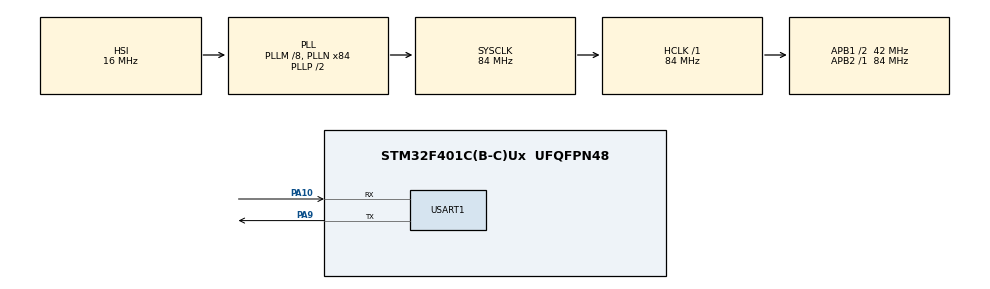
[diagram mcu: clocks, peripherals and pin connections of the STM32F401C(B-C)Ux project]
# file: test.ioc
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Mcu.Family=STM32F4
Mcu.Name=STM32F401C(B-C)Ux
Mcu.Package=UFQFPN48
NVIC.PriorityGroup=NVIC_PRIORITYGROUP_4
PA10.Mode=Asynchronous
PA10.Signal=USART1_RX
PA13.Mode=Serial_Wire
PA13.Signal=SYS_JTMS-SWDIO
PA14.Mode=Serial_Wire
PA14.Signal=SYS_JTCK-SWCLK
PA9.Mode=Asynchronous
PA9.Signal=USART1_TX
PC14-OSC32_IN.Mode=LSE-External-Oscillator
PC14-OSC32_IN.Signal=RCC_OSC32_IN
PC15-OSC32_OUT.Mode=LSE-External-Oscillator
PC15-OSC32_OUT.Signal=RCC_OSC32_OUT
PH0\ -\ OSC_IN.Mode=HSE-External-Oscillator
PH0\ -\ OSC_IN.Signal=RCC_OSC_IN
PH1\ -\ OSC_OUT.Mode=HSE-External-Oscillator
PH1\ -\ OSC_OUT.Signal=RCC_OSC_OUT
ProjectManager.HeapSize=0x200
ProjectManager.StackSize=0x400
ProjectManager.TargetToolchain=EWARM V8
RCC.48MHZClocksFreq_Value=42000000
RCC.AHBFreq_Value=84000000
RCC.APB1CLKDivider=RCC_HCLK_DIV2
RCC.APB1Freq_Value=42000000
RCC.APB1TimFreq_Value=84000000
RCC.APB2Freq_Value=84000000
RCC.APB2TimFreq_Value=84000000
RCC.CortexFreq_Value=84000000
RCC.HCLKFreq_Value=84000000
RCC.HSE_VALUE=25000000
RCC.HSI_VALUE=16000000
RCC.PLLM=8
RCC.PLLN=84
RCC.SYSCLKFreq_VALUE=84000000
RCC.SYSCLKSource=RCC_SYSCLKSOURCE_PLLCLK
RCC.VCOOutputFreq_Value=168000000
USART1.VirtualMode=VM_ASYNC
board=custom

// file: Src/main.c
/* USER CODE BEGIN Header */
/**
  ******************************************************************************
  * @file           : main.c
  * @brief          : Main program body
  ******************************************************************************
  * @attention
  *
  * <h2><center>&copy; Copyright (c) 2020 STMicroelectronics.
  * All rights reserved.</center></h2>
  *
  * This software component is licensed by ST under BSD 3-Clause license,
  * the "License"; You may not use this file except in compliance with the
  * License. You may obtain a copy of the License at:
  *                        opensource.org/licenses/BSD-3-Clause
  *
  ******************************************************************************
  */
/* USER CODE END Header */

#include "main.h"

UART_HandleTypeDef huart1;

void SystemClock_Config(void);
static void MX_GPIO_Init(void);
static void MX_USART1_UART_Init(void);

int main(void)
{

  /* MCU Configuration--------------------------------------------------------*/

  /* Reset of all peripherals, Initializes the Flash interface and the Systick. */
  HAL_Init();

  /* Configure the system clock */
  SystemClock_Config();

  /* Initialize all configured peripherals */
  MX_GPIO_Init();
  MX_USART1_UART_Init();

  /* Infinite loop */
  while (1)
  {

	/* USER CODE BEGIN 3 */
	char str[] = "hello world\n";
    HAL_UART_Transmit(&huart1,(uint8_t *)str,sizeof(str),1000);
    HAL_Delay(1000);
  }
  /* USER CODE END 3 */
}

void SystemClock_Config(void)
{
  RCC_OscInitTypeDef RCC_OscInitStruct = {0};
  RCC_ClkInitTypeDef RCC_ClkInitStruct = {0};

  /** Configure the main internal regulator output voltage
  */
  __HAL_RCC_PWR_CLK_ENABLE();
  __HAL_PWR_VOLTAGESCALING_CONFIG(PWR_REGULATOR_VOLTAGE_SCALE2);
  /** Initializes the CPU, AHB and APB busses clocks
  */
  RCC_OscInitStruct.OscillatorType = RCC_OSCILLATORTYPE_HSI;
  RCC_OscInitStruct.HSIState = RCC_HSI_ON;
  RCC_OscInitStruct.HSICalibrationValue = RCC_HSICALIBRATION_DEFAULT;
  RCC_OscInitStruct.PLL.PLLState = RCC_PLL_ON;
  RCC_OscInitStruct.PLL.PLLSource = RCC_PLLSOURCE_HSI;
  RCC_OscInitStruct.PLL.PLLM = 8;
  RCC_OscInitStruct.PLL.PLLN = 84;
  RCC_OscInitStruct.PLL.PLLP = RCC_PLLP_DIV2;
  RCC_OscInitStruct.PLL.PLLQ = 4;
  if (HAL_RCC_OscConfig(&RCC_OscInitStruct) != HAL_OK)
  {
    Error_Handler();
  }
  /** Initializes the CPU, AHB and APB busses clocks
  */
  RCC_ClkInitStruct.ClockType = RCC_CLOCKTYPE_HCLK|RCC_CLOCKTYPE_SYSCLK
                              |RCC_CLOCKTYPE_PCLK1|RCC_CLOCKTYPE_PCLK2;
  RCC_ClkInitStruct.SYSCLKSource = RCC_SYSCLKSOURCE_PLLCLK;
  RCC_ClkInitStruct.AHBCLKDivider = RCC_SYSCLK_DIV1;
  RCC_ClkInitStruct.APB1CLKDivider = RCC_HCLK_DIV2;
  RCC_ClkInitStruct.APB2CLKDivider = RCC_HCLK_DIV1;

  if (HAL_RCC_ClockConfig(&RCC_ClkInitStruct, FLASH_LATENCY_2) != HAL_OK)
  {
    Error_Handler();
  }
}

static void MX_USART1_UART_Init(void)
{

  huart1.Instance = USART1;
  huart1.Init.BaudRate = 115200;
  huart1.Init.WordLength = UART_WORDLENGTH_8B;
  huart1.Init.StopBits = UART_STOPBITS_1;
  huart1.Init.Parity = UART_PARITY_NONE;
  huart1.Init.Mode = UART_MODE_TX_RX;
  huart1.Init.HwFlowCtl = UART_HWCONTROL_NONE;
  huart1.Init.OverSampling = UART_OVERSAMPLING_16;
  if (HAL_UART_Init(&huart1) != HAL_OK)
  {
    Error_Handler();
  }

}

static void MX_GPIO_Init(void)
{
  GPIO_InitTypeDef GPIO_InitStruct = {0};

  /* GPIO Ports Clock Enable */
  __HAL_RCC_GPIOC_CLK_ENABLE();
  __HAL_RCC_GPIOH_CLK_ENABLE();
  __HAL_RCC_GPIOA_CLK_ENABLE();
  __HAL_RCC_GPIOB_CLK_ENABLE();

  /*Configure GPIO pin : PC13 */
  GPIO_InitStruct.Pin = GPIO_PIN_13;
  GPIO_InitStruct.Mode = GPIO_MODE_ANALOG;
  GPIO_InitStruct.Pull = GPIO_NOPULL;
  HAL_GPIO_Init(GPIOC, &GPIO_InitStruct);

  /*Configure GPIO pins : PA0 PA1 PA2 PA3
                           PA4 PA5 PA6 PA7
                           PA8 PA11 PA12 PA15 */
  GPIO_InitStruct.Pin = GPIO_PIN_0|GPIO_PIN_1|GPIO_PIN_2|GPIO_PIN_3
                          |GPIO_PIN_4|GPIO_PIN_5|GPIO_PIN_6|GPIO_PIN_7
                          |GPIO_PIN_8|GPIO_PIN_11|GPIO_PIN_12|GPIO_PIN_15;
  GPIO_InitStruct.Mode = GPIO_MODE_ANALOG;
  GPIO_InitStruct.Pull = GPIO_NOPULL;
  HAL_GPIO_Init(GPIOA, &GPIO_InitStruct);

  /*Configure GPIO pins : PB0 PB1 PB2 PB10
                           PB12 PB13 PB14 PB15
                           PB3 PB4 PB5 PB6
                           PB7 PB8 PB9 */
  GPIO_InitStruct.Pin = GPIO_PIN_0|GPIO_PIN_1|GPIO_PIN_2|GPIO_PIN_10
                          |GPIO_PIN_12|GPIO_PIN_13|GPIO_PIN_14|GPIO_PIN_15
                          |GPIO_PIN_3|GPIO_PIN_4|GPIO_PIN_5|GPIO_PIN_6
                          |GPIO_PIN_7|GPIO_PIN_8|GPIO_PIN_9;
  GPIO_InitStruct.Mode = GPIO_MODE_ANALOG;
  GPIO_InitStruct.Pull = GPIO_NOPULL;
  HAL_GPIO_Init(GPIOB, &GPIO_InitStruct);

}

void Error_Handler(void)
{
}

/************************ (C) COPYRIGHT STMicroelectronics *****END OF FILE****/
